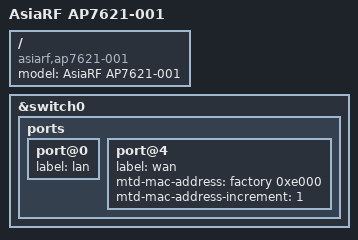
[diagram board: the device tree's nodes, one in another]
// SPDX-License-Identifier: GPL-2.0-or-later OR MIT

#include "mt7621_asiarf_ap7621.dtsi"

/ {
	compatible = "asiarf,ap7621-001", "mediatek,mt7621-soc";
	model = "AsiaRF AP7621-001";
};

&switch0 {
	ports {
		port@0 {
			status = "okay";
			label = "lan";
		};

		port@4 {
			status = "okay";
			label = "wan";
			mtd-mac-address = <&factory 0xe000>;
			mtd-mac-address-increment = <1>;
		};
	};
};
